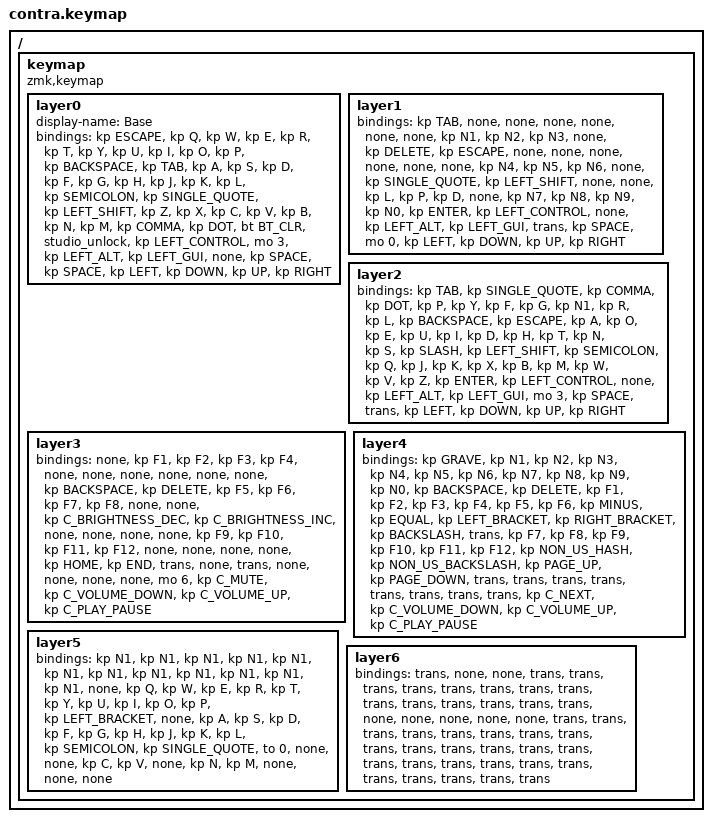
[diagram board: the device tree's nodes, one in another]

  /*
  * Copyright (c) 2020 The ZMK Contributors
  *
  * SPDX-License-Identifier: MIT
  * Adding this because it wont push?
  */

  #include <behaviors.dtsi>
  #include <dt-bindings/zmk/keys.h>
  #include <dt-bindings/zmk/bt.h>
  #include <dt-bindings/zmk/ext_power.h>

  / {
    keymap {
      compatible = "zmk,keymap";
      layer0 {
        display-name = "Base";
          bindings = <
          &kp ESCAPE &kp Q &kp W &kp E &kp R &kp T &kp Y &kp U &kp I &kp O &kp P &kp BACKSPACE &kp TAB &kp A &kp S &kp D &kp F &kp G &kp H &kp J &kp K &kp L &kp SEMICOLON &kp SINGLE_QUOTE &kp LEFT_SHIFT &kp Z &kp X &kp C &kp V &kp B &kp N &kp M &kp COMMA &kp DOT &bt BT_CLR &studio_unlock &kp LEFT_CONTROL &mo 3 &kp LEFT_ALT &kp LEFT_GUI &none &kp SPACE &kp SPACE &kp LEFT &kp DOWN &kp UP &kp RIGHT
          >;
        };layer1 {
          bindings = <
          &kp TAB &none &none &none &none &none &none &kp N1 &kp N2 &kp N3 &none &kp DELETE &kp ESCAPE &none &none &none &none &none &none &kp N4 &kp N5 &kp N6 &none &kp SINGLE_QUOTE &kp LEFT_SHIFT &none &none &kp L &kp P &kp D &none &kp N7 &kp N8 &kp N9 &kp N0 &kp ENTER &kp LEFT_CONTROL &none &kp LEFT_ALT &kp LEFT_GUI &trans &kp SPACE &mo 0 &kp LEFT &kp DOWN &kp UP &kp RIGHT
          >;
        };layer2 {
          bindings = <
          &kp TAB &kp SINGLE_QUOTE &kp COMMA &kp DOT &kp P &kp Y &kp F &kp G &kp N1 &kp R &kp L &kp BACKSPACE &kp ESCAPE &kp A &kp O &kp E &kp U &kp I &kp D &kp H &kp T &kp N &kp S &kp SLASH &kp LEFT_SHIFT &kp SEMICOLON &kp Q &kp J &kp K &kp X &kp B &kp M &kp W &kp V &kp Z &kp ENTER &kp LEFT_CONTROL &none &kp LEFT_ALT &kp LEFT_GUI &mo 3 &kp SPACE &trans &kp LEFT &kp DOWN &kp UP &kp RIGHT
          >;
        };layer3 {
          bindings = <
          &none &kp F1 &kp F2 &kp F3 &kp F4 &none &none &none &none &none &none &kp BACKSPACE &kp DELETE &kp F5 &kp F6 &kp F7 &kp F8 &none &none &kp C_BRIGHTNESS_DEC &kp C_BRIGHTNESS_INC &none &none &none &none &kp F9 &kp F10 &kp F11 &kp F12 &none &none &none &none &kp HOME &kp END &trans &none &trans &none &none &none &none &mo 6 &kp C_MUTE &kp C_VOLUME_DOWN &kp C_VOLUME_UP &kp C_PLAY_PAUSE
          >;
        };layer4 {
          bindings = <
          &kp GRAVE &kp N1 &kp N2 &kp N3 &kp N4 &kp N5 &kp N6 &kp N7 &kp N8 &kp N9 &kp N0 &kp BACKSPACE &kp DELETE &kp F1 &kp F2 &kp F3 &kp F4 &kp F5 &kp F6 &kp MINUS &kp EQUAL &kp LEFT_BRACKET &kp RIGHT_BRACKET &kp BACKSLASH &trans &kp F7 &kp F8 &kp F9 &kp F10 &kp F11 &kp F12 &kp NON_US_HASH &kp NON_US_BACKSLASH &kp PAGE_UP &kp PAGE_DOWN &trans &trans &trans &trans &trans &trans &trans &trans &kp C_NEXT &kp C_VOLUME_DOWN &kp C_VOLUME_UP &kp C_PLAY_PAUSE
          >;
        };layer5 {
          bindings = <
          &kp N1 &kp N1 &kp N1 &kp N1 &kp N1 &kp N1 &kp N1 &kp N1 &kp N1 &kp N1 &kp N1 &kp N1 &none &kp Q &kp W &kp E &kp R &kp T &kp Y &kp U &kp I &kp O &kp P &kp LEFT_BRACKET &none &kp A &kp S &kp D &kp F &kp G &kp H &kp J &kp K &kp L &kp SEMICOLON &kp SINGLE_QUOTE &to 0 &none &none &kp C &kp V &none &kp N &kp M &none &none &none
          >;
        };layer6 {
          bindings = <
          &trans &none &none &trans &trans &trans &trans &trans &trans &trans &trans &trans &trans &trans &trans &trans &trans &none &none &none &none &none &trans &trans &trans &trans &trans &trans &trans &trans &trans &trans &trans &trans &trans &trans &trans &trans &trans &trans &trans &trans &trans &trans &trans &trans &trans
          >;
        };
    };
  };
  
